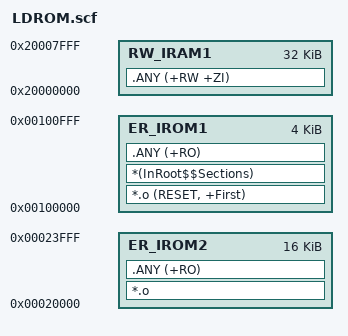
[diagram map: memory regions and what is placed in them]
LR_IROM1 0x00100000 0x1000  {    ; load region size_region
  ER_IROM1 0x00100000 0x1000  {  ; load address = execution address
   *.o (RESET, +First)
   *(InRoot$$Sections)
   .ANY (+RO)
  }
  RW_IRAM1 0x20000000 0x00008000  {  ; RW data
   .ANY (+RW +ZI)
  }
}

LR_IROM2 0x00020000 0x4000  {    ; load region size_region
  ER_IROM2 0x00020000   0x4000{  ; load address = execution address
  *.o
   .ANY (+RO)
  }
 }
